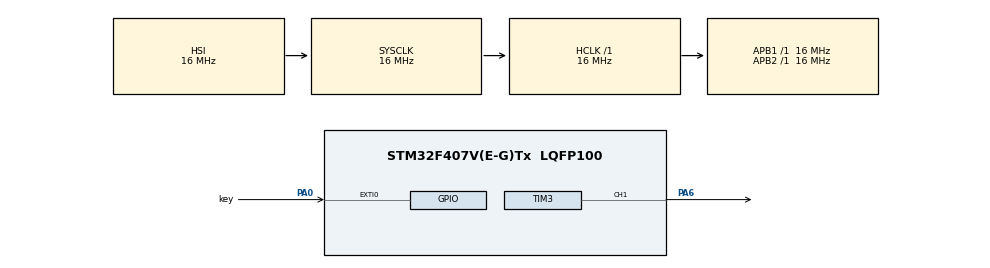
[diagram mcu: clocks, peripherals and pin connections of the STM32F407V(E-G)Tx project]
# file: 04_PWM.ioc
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Mcu.Family=STM32F4
Mcu.Name=STM32F407V(E-G)Tx
Mcu.Package=LQFP100
NVIC.EXTI0_IRQn=true\:0\:0\:false\:false\:true\:true\:true\:true
NVIC.PriorityGroup=NVIC_PRIORITYGROUP_4
NVIC.TIM3_IRQn=true\:0\:0\:false\:false\:true\:true\:true\:true
PA0-WKUP.GPIO_Label=key
PA0-WKUP.Signal=GPXTI0
PA13.Mode=Serial_Wire
PA13.Signal=SYS_JTMS-SWDIO
PA14.Mode=Serial_Wire
PA14.Signal=SYS_JTCK-SWCLK
PA6.Signal=S_TIM3_CH1
ProjectManager.HeapSize=0x200
ProjectManager.StackSize=0x400
ProjectManager.TargetToolchain=STM32CubeIDE
RCC.AHBFreq_Value=16000000
RCC.APB1Freq_Value=16000000
RCC.APB2Freq_Value=16000000
RCC.CortexFreq_Value=16000000
RCC.HSE_VALUE=25000000
RCC.HSI_VALUE=16000000
RCC.LSE_VALUE=32768
RCC.SYSCLKFreq_VALUE=16000000
RCC.VCOOutputFreq_Value=192000000
SH.S_TIM3_CH1.0=TIM3_CH1,PWM Generation1 CH1
TIM3.Channel-PWM\ Generation1\ CH1=TIM_CHANNEL_1
TIM3.CounterMode=TIM_COUNTERMODE_DOWN
TIM3.Period=100-1
TIM3.Prescaler=1600-1
VP_TIM3_VS_ClockSourceINT.Mode=Internal
board=custom

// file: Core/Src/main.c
/* USER CODE BEGIN Header */
/**
 ******************************************************************************
 * @file           : main.c
 * @brief          : Main program body
 ******************************************************************************
 * @attention
 *
 * Copyright (c) 2023 STMicroelectronics.
 * All rights reserved.
 *
 * This software is licensed under terms that can be found in the LICENSE file
 * in the root directory of this software component.
 * If no LICENSE file comes with this software, it is provided AS-IS.
 *
 ******************************************************************************
 */
/* USER CODE END Header */
#include "main.h"

TIM_HandleTypeDef htim3;

/* USER CODE BEGIN PV */
int button_CNT = 0; // подсчет кнопки
int brightness = 50; // значение яркости - в начале 50%
int step = 1; // +1 / -1
/* USER CODE END PV */

void SystemClock_Config(void);
static void MX_GPIO_Init(void);
static void MX_TIM3_Init(void);
/* USER CODE BEGIN PFP */
void EXTI0_IRQHandler(void) {
	if (__HAL_GPIO_EXTI_GET_IT(key_Pin) != RESET) {
		__HAL_GPIO_EXTI_CLEAR_IT(key_Pin);
		button_CNT = 0;
	}
}

void SysTick_Handler() // запускается каждую мс
{
	button_CNT += GPIOA->IDR & 0x1; // дребезг
}

// Период переполнения таймера SysTick
int getSysTickDelay() {
	int callibrate = (SysTick->CTRL & 0b100) ? 1 : 8; // делитель AHB (из лекции)
	int frequency = HAL_RCC_GetSysClockFreq() / callibrate; // частота системного тактового сигнала
	int ticks = (SysTick->LOAD + 1); // пороговое значение сброса таймера
	return ticks * 1000 / frequency;
}

// Период переполнения таймера 3
int getTim3Delay() {
	int callibrate = (SysTick->CTRL & 0b100) ? 1 : 8; // делитель AHB (из лекции)
	int frequency = HAL_RCC_GetSysClockFreq() / callibrate; // частота системного тактового сигнала
	frequency /= (TIM3->PSC + 1); // Поделить на прескейлер
	int ticks = (TIM3->ARR + 1); // пороговое значение сброса таймера
	return ticks * 1000 / frequency; // 1 мс
}

/* USER CODE END PFP */

int main(void)
{
  /* USER CODE BEGIN 1 */

	// В графическом интерфейсе включить таймер (3) и выбрать один из 4 каналов (1),
	// поставить его в режим Output Compare CH (Mode - Toggle on match).
	// Со таймером 2 по непонятной причине не пошло.
	// В значении делителя поставить что-нибудь кратное частоте и не слишком большое (16МГц -> 160).
	// Период взят 100 для представления в процентах.
	// Включить прерывания таймера и EXTI line 0.
	// Тактирование включать не требуется.
	// Соединить перемычкой пин канала таймера (PA6) и пин диода (PD13 / PG13).

	// LED в режим input (по умолчанию)
	GPIOD->MODER &= ~(3 << (2 * 13)); // PD13 to 00
	GPIOA->MODER &= ~3; // PA0 to 00
  /* USER CODE END 1 */

  /* MCU Configuration--------------------------------------------------------*/

  /* Reset of all peripherals, Initializes the Flash interface and the Systick. */
  HAL_Init();

  /* Configure the system clock */
  SystemClock_Config();

  /* Initialize all configured peripherals */
  MX_GPIO_Init();
  MX_TIM3_Init();
  /* USER CODE BEGIN 2 */
	TIM3->CCER |= TIM_CCER_CC1E; // Включить вывод 1 канала
	TIM3->CCR1 = brightness; // Средняя яркость вначале
	TIM3->CR1 |= TIM_CR1_CEN; // Включить таймер
  /* USER CODE END 2 */

  /* Infinite loop */
  /* USER CODE BEGIN WHILE */
	while (1) {
		if (button_CNT > 50) {
			// Переключить в режим уменьшения/добавления яркости
			if (brightness + step >= TIM3->ARR || brightness < 0)
				step *= -1;
			// Прибавить шаг якрости
			brightness += step;
			// Сбросить кнопку
			button_CNT = 0;
			// Установить скважность
			TIM3->CCR1 = brightness;
		}
    /* USER CODE END WHILE */

	}
}

void SystemClock_Config(void)
{
  RCC_OscInitTypeDef RCC_OscInitStruct = {0};
  RCC_ClkInitTypeDef RCC_ClkInitStruct = {0};

  /** Configure the main internal regulator output voltage
  */
  __HAL_RCC_PWR_CLK_ENABLE();
  __HAL_PWR_VOLTAGESCALING_CONFIG(PWR_REGULATOR_VOLTAGE_SCALE1);

  /** Initializes the RCC Oscillators according to the specified parameters
  * in the RCC_OscInitTypeDef structure.
  */
  RCC_OscInitStruct.OscillatorType = RCC_OSCILLATORTYPE_HSI;
  RCC_OscInitStruct.HSIState = RCC_HSI_ON;
  RCC_OscInitStruct.HSICalibrationValue = RCC_HSICALIBRATION_DEFAULT;
  RCC_OscInitStruct.PLL.PLLState = RCC_PLL_NONE;
  if (HAL_RCC_OscConfig(&RCC_OscInitStruct) != HAL_OK)
  {
    Error_Handler();
  }

  /** Initializes the CPU, AHB and APB buses clocks
  */
  RCC_ClkInitStruct.ClockType = RCC_CLOCKTYPE_HCLK|RCC_CLOCKTYPE_SYSCLK
                              |RCC_CLOCKTYPE_PCLK1|RCC_CLOCKTYPE_PCLK2;
  RCC_ClkInitStruct.SYSCLKSource = RCC_SYSCLKSOURCE_HSI;
  RCC_ClkInitStruct.AHBCLKDivider = RCC_SYSCLK_DIV1;
  RCC_ClkInitStruct.APB1CLKDivider = RCC_HCLK_DIV1;
  RCC_ClkInitStruct.APB2CLKDivider = RCC_HCLK_DIV1;

  if (HAL_RCC_ClockConfig(&RCC_ClkInitStruct, FLASH_LATENCY_0) != HAL_OK)
  {
    Error_Handler();
  }
}

static void MX_TIM3_Init(void)
{

  TIM_ClockConfigTypeDef sClockSourceConfig = {0};
  TIM_MasterConfigTypeDef sMasterConfig = {0};
  TIM_OC_InitTypeDef sConfigOC = {0};

  htim3.Instance = TIM3;
  htim3.Init.Prescaler = 1600-1;
  htim3.Init.CounterMode = TIM_COUNTERMODE_DOWN;
  htim3.Init.Period = 100-1;
  htim3.Init.ClockDivision = TIM_CLOCKDIVISION_DIV1;
  htim3.Init.AutoReloadPreload = TIM_AUTORELOAD_PRELOAD_DISABLE;
  if (HAL_TIM_Base_Init(&htim3) != HAL_OK)
  {
    Error_Handler();
  }
  sClockSourceConfig.ClockSource = TIM_CLOCKSOURCE_INTERNAL;
  if (HAL_TIM_ConfigClockSource(&htim3, &sClockSourceConfig) != HAL_OK)
  {
    Error_Handler();
  }
  if (HAL_TIM_PWM_Init(&htim3) != HAL_OK)
  {
    Error_Handler();
  }
  sMasterConfig.MasterOutputTrigger = TIM_TRGO_RESET;
  sMasterConfig.MasterSlaveMode = TIM_MASTERSLAVEMODE_DISABLE;
  if (HAL_TIMEx_MasterConfigSynchronization(&htim3, &sMasterConfig) != HAL_OK)
  {
    Error_Handler();
  }
  sConfigOC.OCMode = TIM_OCMODE_PWM1;
  sConfigOC.Pulse = 0;
  sConfigOC.OCPolarity = TIM_OCPOLARITY_HIGH;
  sConfigOC.OCFastMode = TIM_OCFAST_DISABLE;
  if (HAL_TIM_PWM_ConfigChannel(&htim3, &sConfigOC, TIM_CHANNEL_1) != HAL_OK)
  {
    Error_Handler();
  }
  HAL_TIM_MspPostInit(&htim3);

}

static void MX_GPIO_Init(void)
{
  GPIO_InitTypeDef GPIO_InitStruct = {0};

  /* GPIO Ports Clock Enable */
  __HAL_RCC_GPIOA_CLK_ENABLE();

  /*Configure GPIO pin : key_Pin */
  GPIO_InitStruct.Pin = key_Pin;
  GPIO_InitStruct.Mode = GPIO_MODE_IT_RISING;
  GPIO_InitStruct.Pull = GPIO_NOPULL;
  HAL_GPIO_Init(key_GPIO_Port, &GPIO_InitStruct);

  /* EXTI interrupt init*/
  HAL_NVIC_SetPriority(EXTI0_IRQn, 0, 0);
  HAL_NVIC_EnableIRQ(EXTI0_IRQn);

}

void Error_Handler(void)
{
	__disable_irq();
	while (1) {
	}
}
